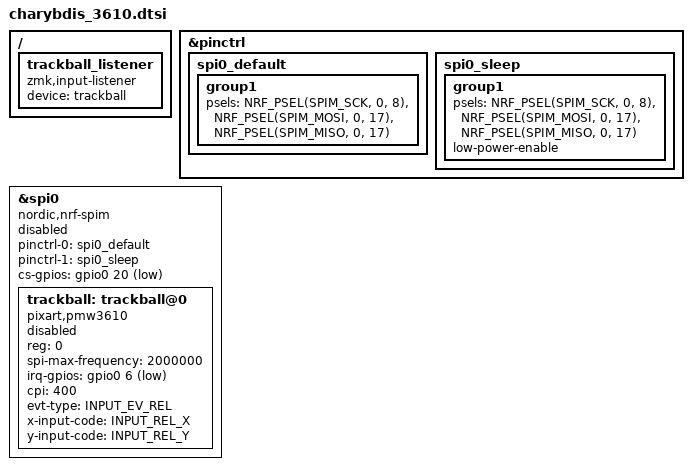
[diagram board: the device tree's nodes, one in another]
#define INPUT_EV_KEY 0x01               /**< Key event */
#define INPUT_EV_REL 0x02               /**< Relative coordinate event */
#define INPUT_EV_ABS 0x03               /**< Absolute coordinate event */
#define INPUT_EV_MSC 0x04               /**< Miscellaneous event */
#define INPUT_EV_VENDOR_START 0xf0      /**< Vendor specific event start */
#define INPUT_EV_VENDOR_STOP 0xff       /**< Vendor specific event stop */

#define INPUT_REL_X 0x00                /**< Relative X coordinate */
#define INPUT_REL_Y 0x01                /**< Relative Y coordinate */
#define INPUT_REL_WHEEL 0x08            /**< Relative wheel coordinate */
#define INPUT_REL_HWHEEL 0x06           /**< Relative horizontal wheel coordinate */
#define INPUT_REL_MISC 0x09             /**< Relative misc coordinate */

&pinctrl {
    spi0_default: spi0_default {
        group1 {
            psels = <NRF_PSEL(SPIM_SCK, 0, 8)>,
                <NRF_PSEL(SPIM_MOSI, 0, 17)>,
                <NRF_PSEL(SPIM_MISO, 0, 17)>;
        };
    };

    spi0_sleep: spi0_sleep {
        group1 {
            psels = <NRF_PSEL(SPIM_SCK, 0, 8)>,
                <NRF_PSEL(SPIM_MOSI, 0, 17)>,
                <NRF_PSEL(SPIM_MISO, 0, 17)>;
            low-power-enable;
        };
    };
};

&spi0 {
    status = "disabled";
    compatible = "nordic,nrf-spim";
    pinctrl-0 = <&spi0_default>;
    pinctrl-1 = <&spi0_sleep>;
    pinctrl-names = "default", "sleep";
    cs-gpios = <&gpio0 20 GPIO_ACTIVE_LOW>;

    trackball: trackball@0 {
        status = "disabled";
        compatible = "pixart,pmw3610";
        reg = <0>;
        spi-max-frequency = <2000000>;
        irq-gpios = <&gpio0 6 (GPIO_ACTIVE_LOW | GPIO_PULL_UP)>;
        /* 2026-08-24: lowered from 1000 to 400 to match the base pointer
         * speed of the charybdis-36 sibling board, which runs its PMW3610
         * (different driver fork, DoctorWangWang) at CONFIG_PMW3610_CPI=1200
         * with CONFIG_PMW3610_CPI_DIVIDOR=4 — an effective ~300 CPI on its
         * base layer. This driver has no software CPI dividor, only the raw
         * 200-CPI-stepped sensor register, so 400 is the closest achievable
         * step (300 itself isn't reachable: the register conversion is
         * cpi/200 with truncation, so 300 would silently become 200).
         * Previously 1000 (~a third of the stock 3200, 2026-07-16 preference)
         * — revisit via the cpi_up/cpi_dn keys if 400 feels too slow. */
        cpi = <400>;
        evt-type = <INPUT_EV_REL>;
        x-input-code = <INPUT_REL_X>;
        y-input-code = <INPUT_REL_Y>;
    };
};
/ {
    /*
     * No-dongle setup: the right half is the split CENTRAL, and ZMK's
     * input-split proxies ONLY peripheral events on the central side — a
     * local `device` on &trackball_split is silently ignored. So the central
     * must listen to the physical sensor directly. The left overlay disables
     * this listener (its &trackball device stays disabled/uninstantiated).
     * Layer-scoped input processors are added to it from the keymap.
     */
    trackball_listener: trackball_listener {
        compatible = "zmk,input-listener";
        device = <&trackball>;
    };
};
